# axil_regfile: IP-XACT component
VLNV liminalnook:motorloop:axil_regfile:0.1.0

## Bus interfaces (logical=physical port)
s_axi: slave amba.com:AMBA4:AXI4Lite:r0p0_0, memory map regs

## Address spaces and blocks
regs.control_telemetry: base 0x0, range 0x100, width 32, register

## Registers
Registers are 32-bit, read-write, no defined reset value unless marked. A register's access mark holds for its fields unless they carry their own. Offsets are from the block's base; lines under a group give offsets from that group; [hi:lo] are bit positions; {n}, {i} and the like mark numbered series; 'fields as' and 'values as' point back to an identical list; <NAME> marks a mode.

## regs.control_telemetry
Base 0x00000000
0x00 mode — control mode (0 idle,1 OL,2 six-step,3 FOC)
  [1:0] mode
0x04 duty — open-loop duty compare
  [15:0] duty
0x08 target_speed — speed target (rad/s)
  [15:0] target_speed
0x0C align — electrical-angle alignment offset
  [11:0] align
0x10 ol_freq_word_hi — open-loop freq word [31:16]
  [15:0] v
0x14 ol_freq_word_lo — open-loop freq word [15:0]
  [15:0] v
0x18 ol_ramp_inc_hi — open-loop ramp increment [31:16]
  [15:0] v
0x1C ol_ramp_inc_lo — open-loop ramp increment [15:0]
  [15:0] v
0x20 control — bit0: AXI overrides direct ctrl_*
  [0] use_axi
0x40 speed ro — measured speed (rad/s)
  [15:0] speed
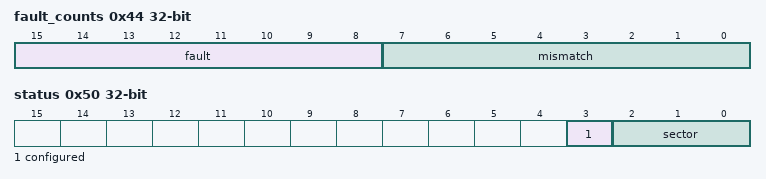
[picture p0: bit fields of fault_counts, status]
0x44 fault_counts ro — fault/mismatch counts
  [15:8] fault, [7:0] mismatch
0x48 angle ro — rotor angle (12-bit)
  [11:0] angle
0x4C noctw_count ro — nOCTW event count
  [15:0] noctw
0x50 status ro — configured + sector
  [3] configured, [2:0] sector
0x54 flags ro — stall/lockout/dead/reverse flags
  [7:0] flags

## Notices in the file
SPDX-License-Identifier: MIT
